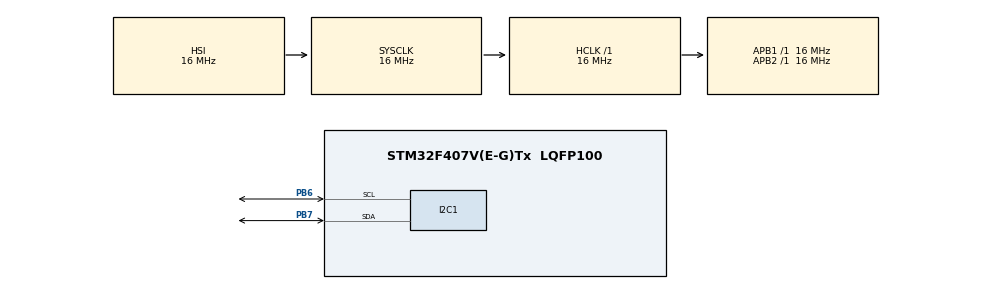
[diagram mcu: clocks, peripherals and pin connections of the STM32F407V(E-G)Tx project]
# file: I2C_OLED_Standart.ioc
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Mcu.Family=STM32F4
Mcu.Name=STM32F407V(E-G)Tx
Mcu.Package=LQFP100
NVIC.PriorityGroup=NVIC_PRIORITYGROUP_4
PB6.Mode=I2C
PB6.Signal=I2C1_SCL
PB7.Mode=I2C
PB7.Signal=I2C1_SDA
ProjectManager.HeapSize=0x200
ProjectManager.StackSize=0x400
ProjectManager.TargetToolchain=MDK-ARM V5
RCC.AHBFreq_Value=16000000
RCC.APB1Freq_Value=16000000
RCC.APB2Freq_Value=16000000
RCC.CortexFreq_Value=16000000
RCC.HSE_VALUE=25000000
RCC.HSI_VALUE=16000000
RCC.SYSCLKFreq_VALUE=16000000
RCC.VCOOutputFreq_Value=192000000
board=custom

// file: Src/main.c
/**
  ******************************************************************************
  * @file           : main.c
  * @brief          : Main program body
  ******************************************************************************
  ** This notice applies to any and all portions of this file
  * that are not between comment pairs USER CODE BEGIN and
  * USER CODE END. Other portions of this file, whether
  * inserted by the user or by software development tools
  * are owned by their respective copyright owners.
  *
  * COPYRIGHT(c) 2018 STMicroelectronics
  *
  * Redistribution and use in source and binary forms, with or without modification,
  * are permitted provided that the following conditions are met:
  *   1. Redistributions of source code must retain the above copyright notice,
  *      this list of conditions and the following disclaimer.
  *   2. Redistributions in binary form must reproduce the above copyright notice,
  *      this list of conditions and the following disclaimer in the documentation
  *      and/or other materials provided with the distribution.
  *   3. Neither the name of STMicroelectronics nor the names of its contributors
  *      may be used to endorse or promote products derived from this software
  *      without specific prior written permission.
  *
  * THIS SOFTWARE IS PROVIDED BY THE COPYRIGHT HOLDERS AND CONTRIBUTORS "AS IS"
  * AND ANY EXPRESS OR IMPLIED WARRANTIES, INCLUDING, BUT NOT LIMITED TO, THE
  * IMPLIED WARRANTIES OF MERCHANTABILITY AND FITNESS FOR A PARTICULAR PURPOSE ARE
  * DISCLAIMED. IN NO EVENT SHALL THE COPYRIGHT HOLDER OR CONTRIBUTORS BE LIABLE
  * FOR ANY DIRECT, INDIRECT, INCIDENTAL, SPECIAL, EXEMPLARY, OR CONSEQUENTIAL
  * DAMAGES (INCLUDING, BUT NOT LIMITED TO, PROCUREMENT OF SUBSTITUTE GOODS OR
  * SERVICES; LOSS OF USE, DATA, OR PROFITS; OR BUSINESS INTERRUPTION) HOWEVER
  * CAUSED AND ON ANY THEORY OF LIABILITY, WHETHER IN CONTRACT, STRICT LIABILITY,
  * OR TORT (INCLUDING NEGLIGENCE OR OTHERWISE) ARISING IN ANY WAY OUT OF THE USE
  * OF THIS SOFTWARE, EVEN IF ADVISED OF THE POSSIBILITY OF SUCH DAMAGE.
  *
  ******************************************************************************
  */
#include "main.h"
#include "stm32f4xx_hal.h"
#include "fonts.h"
#include "ssd1306.h"

I2C_HandleTypeDef hi2c1;

/* USER CODE BEGIN PV */
/* Private variables ---------------------------------------------------------*/
uint8_t SSD1306_ADDRESS;
/* USER CODE END PV */

void SystemClock_Config(void);
static void MX_GPIO_Init(void);
static void MX_I2C1_Init(void);
void scanI2C_SSD1306(void);

/* USER CODE BEGIN PFP */
/* Private function prototypes -----------------------------------------------*/

/* USER CODE END PFP */

int main(void)
{

  /* MCU Configuration----------------------------------------------------------*/

  /* Reset of all peripherals, Initializes the Flash interface and the Systick. */
  HAL_Init();

  /* Configure the system clock */
  SystemClock_Config();

  /* Initialize all configured peripherals */
  MX_GPIO_Init();
  MX_I2C1_Init();
	scanI2C_SSD1306();
	ssd1306_Init();
	ssd1306_Fill(White);
	ssd1306_UpdateScreen();
  /* USER CODE BEGIN 2 */
	HAL_Delay(1000);
	ssd1306_SetCursor(14,23);
	ssd1306_WriteString("OLED Test",Font_11x18,Black);
	ssd1306_UpdateScreen();
  /* USER CODE END 2 */

  /* Infinite loop */
  while (1)
  {

  }

}

void scanI2C_SSD1306()
{
	uint8_t set=0,i=0;
	while(set == 0)
	{
		if((HAL_I2C_IsDeviceReady(&hi2c1,i,1,10) == HAL_OK) && (i == 0x78))
		{
			SSD1306_ADDRESS = i;
			set = 1;
		}
		else if(i==255)
		{
			i = 0;
			set = 0;
		}
		i++;
	}
}

void SystemClock_Config(void)
{

  RCC_OscInitTypeDef RCC_OscInitStruct;
  RCC_ClkInitTypeDef RCC_ClkInitStruct;

    /**Configure the main internal regulator output voltage
    */
  __HAL_RCC_PWR_CLK_ENABLE();

  __HAL_PWR_VOLTAGESCALING_CONFIG(PWR_REGULATOR_VOLTAGE_SCALE1);

    /**Initializes the CPU, AHB and APB busses clocks
    */
  RCC_OscInitStruct.OscillatorType = RCC_OSCILLATORTYPE_HSI;
  RCC_OscInitStruct.HSIState = RCC_HSI_ON;
  RCC_OscInitStruct.HSICalibrationValue = 16;
  RCC_OscInitStruct.PLL.PLLState = RCC_PLL_NONE;
  if (HAL_RCC_OscConfig(&RCC_OscInitStruct) != HAL_OK)
  {
    _Error_Handler(__FILE__, __LINE__);
  }

    /**Initializes the CPU, AHB and APB busses clocks
    */
  RCC_ClkInitStruct.ClockType = RCC_CLOCKTYPE_HCLK|RCC_CLOCKTYPE_SYSCLK
                              |RCC_CLOCKTYPE_PCLK1|RCC_CLOCKTYPE_PCLK2;
  RCC_ClkInitStruct.SYSCLKSource = RCC_SYSCLKSOURCE_HSI;
  RCC_ClkInitStruct.AHBCLKDivider = RCC_SYSCLK_DIV1;
  RCC_ClkInitStruct.APB1CLKDivider = RCC_HCLK_DIV1;
  RCC_ClkInitStruct.APB2CLKDivider = RCC_HCLK_DIV1;

  if (HAL_RCC_ClockConfig(&RCC_ClkInitStruct, FLASH_LATENCY_0) != HAL_OK)
  {
    _Error_Handler(__FILE__, __LINE__);
  }

    /**Configure the Systick interrupt time
    */
  HAL_SYSTICK_Config(HAL_RCC_GetHCLKFreq()/1000);

    /**Configure the Systick
    */
  HAL_SYSTICK_CLKSourceConfig(SYSTICK_CLKSOURCE_HCLK);

  /* SysTick_IRQn interrupt configuration */
  HAL_NVIC_SetPriority(SysTick_IRQn, 0, 0);
}

/* I2C1 init function */
static void MX_I2C1_Init(void)
{

  hi2c1.Instance = I2C1;
  hi2c1.Init.ClockSpeed = 100000;
  hi2c1.Init.DutyCycle = I2C_DUTYCYCLE_2;
  hi2c1.Init.OwnAddress1 = 0;
  hi2c1.Init.AddressingMode = I2C_ADDRESSINGMODE_7BIT;
  hi2c1.Init.DualAddressMode = I2C_DUALADDRESS_DISABLE;
  hi2c1.Init.OwnAddress2 = 0;
  hi2c1.Init.GeneralCallMode = I2C_GENERALCALL_DISABLE;
  hi2c1.Init.NoStretchMode = I2C_NOSTRETCH_DISABLE;
  if (HAL_I2C_Init(&hi2c1) != HAL_OK)
  {
    _Error_Handler(__FILE__, __LINE__);
  }

}

/** Pinout Configuration
*/
static void MX_GPIO_Init(void)
{

  /* GPIO Ports Clock Enable */
  __HAL_RCC_GPIOB_CLK_ENABLE();

}

void _Error_Handler(char *file, int line)
{
  while(1)
  {
  }
}

/************************ (C) COPYRIGHT STMicroelectronics *****END OF FILE****/
